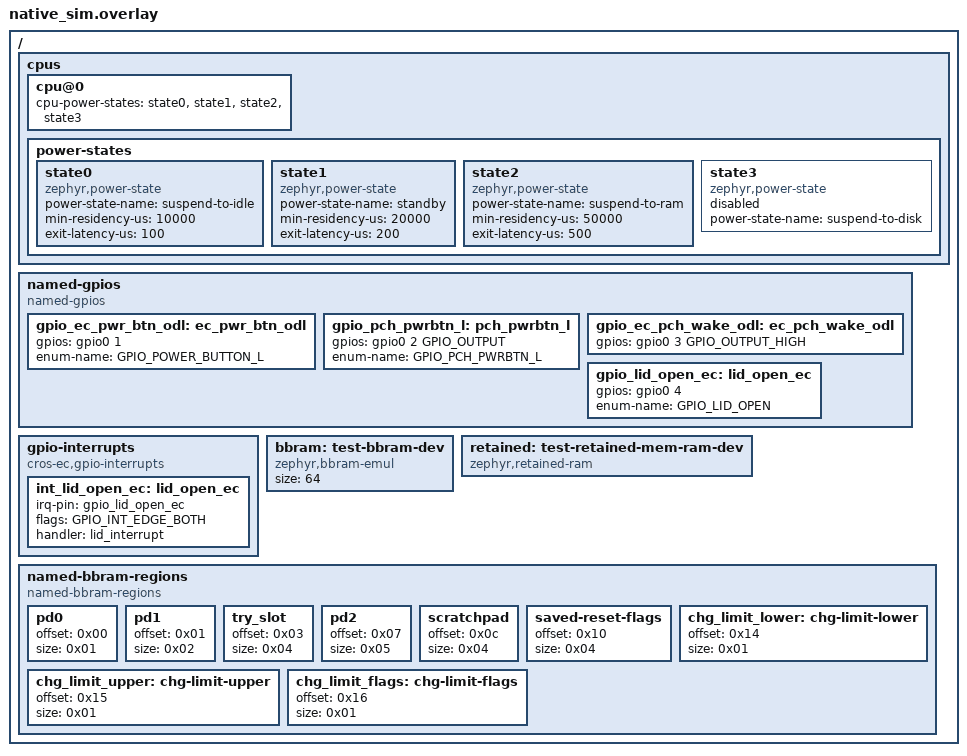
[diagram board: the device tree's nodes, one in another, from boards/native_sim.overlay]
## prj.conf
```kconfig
# Copyright 2021 The ChromiumOS Authors
# Use of this source code is governed by a BSD-style license that can be
# found in the LICENSE file.

CONFIG_ZTEST=y
CONFIG_PLATFORM_EC=y
CONFIG_CROS_EC=y
CONFIG_BBRAM=y

# Make console work
CONFIG_SERIAL=y
CONFIG_SHELL_BACKEND_DUMMY=y
CONFIG_SHELL_BACKEND_DUMMY_BUF_SIZE=1000
CONFIG_SHELL_BACKEND_SERIAL=n

# Make cros_system driver work
CONFIG_PM=y
CONFIG_CROS_SYSTEM_NATIVE_POSIX=y
```

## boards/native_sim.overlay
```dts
/* Copyright 2020 The ChromiumOS Authors
 * Use of this source code is governed by a BSD-style license that can be
 * found in the LICENSE file.
 */

#include <board-overlays/native_sim.dts>

/ {
	cpus {
		cpu@0 {
			cpu-power-states = <&state0 &state1 &state2 &state3>;
		};
		power-states {
			state0: state0 {
				compatible = "zephyr,power-state";
				power-state-name = "suspend-to-idle";
				min-residency-us = <10000>;
				exit-latency-us = <100>;
			};

			state1: state1 {
				compatible = "zephyr,power-state";
				power-state-name = "standby";
				min-residency-us = <20000>;
				exit-latency-us = <200>;
			};

			state2: state2 {
				compatible = "zephyr,power-state";
				power-state-name = "suspend-to-ram";
				min-residency-us = <50000>;
				exit-latency-us = <500>;
			};

			state3: state3 {
				compatible = "zephyr,power-state";
				power-state-name = "suspend-to-disk";
				status = "disabled";
			};
		};
	};
	named-gpios {
		compatible = "named-gpios";

		gpio_ec_pwr_btn_odl: ec_pwr_btn_odl {
			/* GPIO_PULL_UP will cause this start asserted,
			 * i.e. not pressed.
			 */
			gpios = <&gpio0 1 (GPIO_INPUT | GPIO_PULL_UP)>;
			enum-name = "GPIO_POWER_BUTTON_L";
		};
		gpio_pch_pwrbtn_l: pch_pwrbtn_l {
			gpios = <&gpio0 2 GPIO_OUTPUT>;
			enum-name = "GPIO_PCH_PWRBTN_L";
		};
		gpio_ec_pch_wake_odl: ec_pch_wake_odl {
			gpios = <&gpio0 3 GPIO_OUTPUT_HIGH>;
		};
		gpio_lid_open_ec: lid_open_ec {
			/* GPIO_PULL_UP will cause this start asserted. */
			gpios = <&gpio0 4 (GPIO_INPUT | GPIO_PULL_UP)>;
			enum-name = "GPIO_LID_OPEN";
		};
	};
	gpio-interrupts {
		compatible = "cros-ec,gpio-interrupts";

		int_lid_open_ec: lid_open_ec {
			irq-pin = <&gpio_lid_open_ec>;
			flags = <GPIO_INT_EDGE_BOTH>;
			handler = "lid_interrupt";
		};
	};
	bbram: test-bbram-dev {
		compatible = "zephyr,bbram-emul";
		size = <64>;
	};

	retained: test-retained-mem-ram-dev {
		compatible = "zephyr,retained-ram";
	};

	named-bbram-regions {
		compatible = "named-bbram-regions";
		pd0 {
			offset = <0x00>;
			size = <0x01>;
		};
		pd1 {
			offset = <0x01>;
			size = <0x02>;
		};
		try_slot {
			offset = <0x03>;
			size = <0x04>;
		};
		pd2 {
			offset = <0x07>;
			size = <0x05>;
		};
		scratchpad: scratchpad {
			offset = <0x0c>;
			size = <0x04>;
		};
		saved-reset-flags {
			offset = <0x10>;
			size = <0x04>;
		};
		chg_limit_lower: chg-limit-lower {
			offset = <0x14>;
			size = <0x01>;
		};
		chg_limit_upper: chg-limit-upper {
			offset = <0x15>;
			size = <0x01>;
		};
		chg_limit_flags: chg-limit-flags {
			offset = <0x16>;
			size = <0x01>;
		};
	};
};
```

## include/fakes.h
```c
/* Copyright 2022 The ChromiumOS Authors
 * Use of this source code is governed by a BSD-style license that can be
 * found in the LICENSE file.
 */

#ifndef PLATFORM_EC_ZEPHYR_TEST_SYSTEM_SHIM_INCLUDE_FAKES_H_
#define PLATFORM_EC_ZEPHYR_TEST_SYSTEM_SHIM_INCLUDE_FAKES_H_

#include "drivers/cros_system.h"

#include <stdint.h>

#include <zephyr/fff.h>

DECLARE_FAKE_VALUE_FUNC(int, cros_system_get_reset_cause);
DECLARE_FAKE_VALUE_FUNC(uint64_t, cros_system_deep_sleep_ticks);
DECLARE_FAKE_VALUE_FUNC(int, cros_system_hibernate, uint32_t, uint32_t);
DECLARE_FAKE_VALUE_FUNC(int, cros_system_get_hibernate_wake_source,
			enum hibernate_wake_source *);
DECLARE_FAKE_VALUE_FUNC(const char *, cros_system_chip_vendor);
DECLARE_FAKE_VALUE_FUNC(const char *, cros_system_chip_name);
DECLARE_FAKE_VALUE_FUNC(const char *, cros_system_chip_revision);
DECLARE_FAKE_VALUE_FUNC(int, cros_system_soc_reset);
DECLARE_FAKE_VOID_FUNC(watchdog_reload);
DECLARE_FAKE_VOID_FUNC(board_hibernate);

#endif /* PLATFORM_EC_ZEPHYR_TEST_SYSTEM_SHIM_INCLUDE_FAKES_H_ */
```

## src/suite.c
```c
/* Copyright 2022 The ChromiumOS Authors
 * Use of this source code is governed by a BSD-style license that can be
 * found in the LICENSE file.
 */

#include "fakes.h"

#include <zephyr/device.h>
#include <zephyr/drivers/bbram.h>
#include <zephyr/fff.h>
#include <zephyr/ztest.h>

DEFINE_FAKE_VALUE_FUNC(int, cros_system_get_reset_cause);
DEFINE_FAKE_VALUE_FUNC(uint64_t, cros_system_deep_sleep_ticks);
DEFINE_FAKE_VALUE_FUNC(int, cros_system_hibernate, uint32_t, uint32_t);
DEFINE_FAKE_VALUE_FUNC(int, cros_system_get_hibernate_wake_source,
		       enum hibernate_wake_source *);
DEFINE_FAKE_VALUE_FUNC(const char *, cros_system_chip_vendor);
DEFINE_FAKE_VALUE_FUNC(const char *, cros_system_chip_name);
DEFINE_FAKE_VALUE_FUNC(const char *, cros_system_chip_revision);
DEFINE_FAKE_VALUE_FUNC(int, cros_system_soc_reset);
DEFINE_FAKE_VOID_FUNC(watchdog_reload);
DEFINE_FAKE_VOID_FUNC(board_hibernate);

static void system_before_after(void *test_data)
{
#ifdef CONFIG_PLATFORM_EC_BBRAM_TYPE_BBRAM
	const struct device *bbram_dev =
		DEVICE_DT_GET_OR_NULL(DT_CHOSEN(cros_ec_bbram));

	if (bbram_dev != NULL) {
		bbram_emul_set_invalid(bbram_dev, false);
	}
#endif

	RESET_FAKE(cros_system_get_reset_cause);
	RESET_FAKE(cros_system_deep_sleep_ticks);
	RESET_FAKE(cros_system_hibernate);
	RESET_FAKE(cros_system_get_hibernate_wake_source);
	RESET_FAKE(cros_system_chip_vendor);
	RESET_FAKE(cros_system_chip_name);
	RESET_FAKE(cros_system_chip_revision);
	RESET_FAKE(cros_system_soc_reset);
	RESET_FAKE(watchdog_reload);
	RESET_FAKE(board_hibernate);
}

ZTEST_SUITE(system, NULL, NULL, system_before_after, system_before_after, NULL);
```

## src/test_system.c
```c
/* Copyright 2020 The ChromiumOS Authors
 * Use of this source code is governed by a BSD-style license that can be
 * found in the LICENSE file.
 */

#include "bbram.h"
#include "drivers/cros_system.h"
#include "fakes.h"
#include "system.h"

#include <setjmp.h>

#include <zephyr/device.h>
#include <zephyr/drivers/bbram.h>
#include <zephyr/drivers/retained_mem.h>
#include <zephyr/fff.h>
#include <zephyr/logging/log.h>
#include <zephyr/pm/policy.h>
#include <zephyr/pm/state.h>
#include <zephyr/shell/shell_dummy.h>
#include <zephyr/ztest_assert.h>
#include <zephyr/ztest_test.h>

LOG_MODULE_REGISTER(test);

static char mock_data[64] =
	"abcdefghijklmnopqrstuvwxyzABCDEFGHIJKLMNOPQRSTUVWXYZ0123456789!@";

BUILD_ASSERT(sizeof(mock_data) >= BBRAM_REGION_OFFSET(chg_limit_flags) +
					  BBRAM_REGION_SIZE(chg_limit_flags));

int system_preinitialize(const struct device *unused);
int system_bbram_write(const struct device *dev, size_t offset, size_t size,
		       const uint8_t *data);

ZTEST(system, test_invalid_bbram_index)
{
	zassert_equal(EC_ERROR_INVAL,
		      system_get_bbram(SYSTEM_BBRAM_IDX_MAX, NULL));
	zassert_equal(EC_ERROR_INVAL,
		      system_set_bbram(SYSTEM_BBRAM_IDX_MAX, 0));
}

ZTEST(system, test_bbram_get)
{
	const struct device *const bbram_dev =
		DEVICE_DT_GET(DT_CHOSEN(cros_ec_bbram));
	uint8_t output[10];
	int rc;

	/* Write expected data to read back */
	rc = system_bbram_write(bbram_dev, 0, ARRAY_SIZE(mock_data), mock_data);
	zassert_ok(rc);

	rc = system_get_bbram(SYSTEM_BBRAM_IDX_PD0, output);
	zassert_ok(rc);
	zassert_mem_equal(output, mock_data + BBRAM_REGION_OFFSET(pd0),
			  BBRAM_REGION_SIZE(pd0), NULL);

	rc = system_get_bbram(SYSTEM_BBRAM_IDX_PD1, output);
	zassert_ok(rc);
	zassert_mem_equal(output, mock_data + BBRAM_REGION_OFFSET(pd1),
			  BBRAM_REGION_SIZE(pd1), NULL);

	rc = system_get_bbram(SYSTEM_BBRAM_IDX_PD2, output);
	zassert_ok(rc);
	zassert_mem_equal(output, mock_data + BBRAM_REGION_OFFSET(pd2),
			  BBRAM_REGION_SIZE(pd2), NULL);

	rc = system_get_bbram(SYSTEM_BBRAM_IDX_TRY_SLOT, output);
	zassert_ok(rc);
	zassert_mem_equal(output, mock_data + BBRAM_REGION_OFFSET(try_slot),
			  BBRAM_REGION_SIZE(try_slot), NULL);

	rc = system_get_bbram(SYSTEM_BBRAM_IDX_CHG_LIMIT_LOWER, output);
	zassert_ok(rc);
	zassert_mem_equal(output,
			  mock_data + BBRAM_REGION_OFFSET(chg_limit_lower),
			  BBRAM_REGION_SIZE(chg_limit_lower), NULL);

	rc = system_get_bbram(SYSTEM_BBRAM_IDX_CHG_LIMIT_UPPER, output);
	zassert_ok(rc);
	zassert_mem_equal(output,
			  mock_data + BBRAM_REGION_OFFSET(chg_limit_upper),
			  BBRAM_REGION_SIZE(chg_limit_upper), NULL);

	rc = system_get_bbram(SYSTEM_BBRAM_IDX_CHG_LIMIT_FLAGS, output);
	zassert_ok(rc);
	zassert_mem_equal(output,
			  mock_data + BBRAM_REGION_OFFSET(chg_limit_flags),
			  BBRAM_REGION_SIZE(chg_limit_flags), NULL);
}

ZTEST(system, test_bbram_set_get)
{
	uint8_t val;

	zassert_ok(system_set_bbram(SYSTEM_BBRAM_IDX_CHG_LIMIT_LOWER, 80));
	zassert_ok(system_get_bbram(SYSTEM_BBRAM_IDX_CHG_LIMIT_LOWER, &val));
	zassert_equal(val, 80);

	zassert_ok(system_set_bbram(SYSTEM_BBRAM_IDX_CHG_LIMIT_UPPER, 85));
	zassert_ok(system_get_bbram(SYSTEM_BBRAM_IDX_CHG_LIMIT_UPPER, &val));
	zassert_equal(val, 85);

	zassert_ok(system_set_bbram(SYSTEM_BBRAM_IDX_CHG_LIMIT_FLAGS, 1));
	zassert_ok(system_get_bbram(SYSTEM_BBRAM_IDX_CHG_LIMIT_FLAGS, &val));
	zassert_equal(val, 1);
}

ZTEST(system, test_save_read_chip_reset_flags)
{
	uint32_t arbitrary_flags = 0x1234;

	chip_save_reset_flags(0);
	chip_save_reset_flags(arbitrary_flags);
	zassert_equal(chip_read_reset_flags(), arbitrary_flags);
}

static int
custom_cros_system_get_hibernate_wake_source(enum hibernate_wake_source *source)
{
	*source = WAKE_SOURCE_PWR_BTN;
	return 0;
}

/* Test system_get_hibernate_wake_source delegates to cros_system driver */
ZTEST(system, test_system_get_hibernate_wake_source)
{
	enum hibernate_wake_source source = WAKE_SOURCE_UNKNOWN;

	/* Test successful query with custom fake setting the out parameter */
	cros_system_get_hibernate_wake_source_fake.custom_fake =
		custom_cros_system_get_hibernate_wake_source;

	zassert_ok(system_get_hibernate_wake_source(&source));
	zassert_equal(cros_system_get_hibernate_wake_source_fake.call_count, 1);
	zassert_equal(cros_system_get_hibernate_wake_source_fake.arg0_val,
		      &source);
	zassert_equal(source, WAKE_SOURCE_PWR_BTN);

	/* Test error return value is properly forwarded */
	cros_system_get_hibernate_wake_source_fake.custom_fake = NULL;
	cros_system_get_hibernate_wake_source_fake.return_val = -ENOSYS;

	zassert_equal(-ENOSYS, system_get_hibernate_wake_source(&source));
	zassert_equal(cros_system_get_hibernate_wake_source_fake.call_count, 2);
}

ZTEST(system, test_system_set_get_scratchpad)
{
	/* Arbitrary values */
	uint32_t scratch_set = 0x1234;
	uint32_t scratch_read;

	system_set_scratchpad(scratch_set);
	system_get_scratchpad(&scratch_read);
	zassert_equal(scratch_read, scratch_set);
}

#ifdef CONFIG_PLATFORM_EC_BBRAM_TYPE_BBRAM
ZTEST(system, test_system_get_scratchpad_fail)
{
	const struct device *bbram_dev =
		DEVICE_DT_GET(DT_CHOSEN(cros_ec_bbram));

	zassert_ok(bbram_emul_set_invalid(bbram_dev, true));
	zassert_equal(-EC_ERROR_INVAL, system_get_scratchpad(NULL));
}
#endif /* CONFIG_PLATFORM_EC_BBRAM_TYPE_BBRAM */

static jmp_buf jmp_hibernate;

static int _test_cros_system_hibernate(uint32_t seconds, uint32_t microseconds)
{
	longjmp(jmp_hibernate, 1);

	return 0;
}

ZTEST(system, test_system_hibernate)
{
	/*
	 * Due to setjmp usage, this test provides no coverage, but does
	 * actually cover the code. This is due to a bug in LCOV.
	 */
	int ret = setjmp(jmp_hibernate);
	/* Validate 0th and last bit preserved*/
	uint32_t secs = BIT(31) + 1;
	uint32_t msecs = BIT(31) + 3;

	cros_system_hibernate_fake.custom_fake = _test_cros_system_hibernate;

	if (ret == 0) {
		system_hibernate(secs, msecs);
	}

	zassert_not_equal(ret, 0);

	zassert_equal(cros_system_hibernate_fake.call_count, 1);
	zassert_equal(cros_system_hibernate_fake.arg0_val, secs);
	zassert_equal(cros_system_hibernate_fake.arg1_val, msecs);
	zassert_equal(board_hibernate_fake.call_count, 1);
}

ZTEST(system, test_system_hibernate__failure)
{
	/* Validate 0th and last bit preserved*/
	uint32_t secs = BIT(31) + 1;
	uint32_t msecs = BIT(31) + 3;

	cros_system_hibernate_fake.return_val = -1;

	system_hibernate(secs, msecs);

	zassert_equal(cros_system_hibernate_fake.call_count, 1);
	zassert_equal(cros_system_hibernate_fake.arg0_val, secs);
	zassert_equal(cros_system_hibernate_fake.arg1_val, msecs);
}

ZTEST(system, test_system_get_chip_values)
{
	/* Vendor */
	cros_system_chip_vendor_fake.return_val = "a";
	zassert_mem_equal(system_get_chip_vendor(), "a", sizeof("a"));
	zassert_equal(cros_system_chip_vendor_fake.call_count, 1);

	/* Name */
	cros_system_chip_name_fake.return_val = "b";
	zassert_mem_equal(system_get_chip_name(), "b", sizeof("b"));
	zassert_equal(cros_system_chip_name_fake.call_count, 1);

	/* Revision */
	cros_system_chip_revision_fake.return_val = "c";
	zassert_mem_equal(system_get_chip_revision(), "c", sizeof("c"));
	zassert_equal(cros_system_chip_revision_fake.call_count, 1);
}

static int _test_cros_system_soc_reset(void)
{
	printf("called from soc reset");
	longjmp(jmp_hibernate, 1);

	return 0;
}

ZTEST(system, test_system_reset)
{
	/*
	 * Despite using setjmp this test consistently covers the code under
	 * test. Context: https://github.com/llvm/llvm-project/issues/50119
	 */
	int ret = setjmp(jmp_hibernate);
	uint32_t arbitrary_flags_w_reset_wait_ext = 0x1234 |
						    SYSTEM_RESET_WAIT_EXT;
	uint32_t encoded_arbitrary_flags_w_reset_wait_ext;

	system_encode_save_flags(arbitrary_flags_w_reset_wait_ext,
				 &encoded_arbitrary_flags_w_reset_wait_ext);

	cros_system_soc_reset_fake.custom_fake = _test_cros_system_soc_reset;

	if (ret == 0) {
		system_reset(arbitrary_flags_w_reset_wait_ext);
	}

	zassert_equal(chip_read_reset_flags(),
		      encoded_arbitrary_flags_w_reset_wait_ext);

	zassert_equal(watchdog_reload_fake.call_count, 1000);
	zassert_equal(cros_system_soc_reset_fake.call_count, 1);
}

ZTEST_USER(system, test_system_console_cmd__idlestats)
{
	const struct shell *shell_zephyr = get_ec_shell();
	const char *outbuffer;
	size_t buffer_size;

	shell_backend_dummy_clear_output(shell_zephyr);

	k_sleep(K_SECONDS(1));
	zassert_ok(shell_execute_cmd(shell_zephyr, "idlestats"), NULL);

	/* Weakly verify contents */
	outbuffer = shell_backend_dummy_get_output(shell_zephyr, &buffer_size);
	zassert_not_equal(buffer_size, 0);
	zassert_not_null(strstr(outbuffer, "Time spent in deep-sleep:"));
	zassert_not_null(strstr(outbuffer, "Total time on:"));

	zassert_equal(cros_system_deep_sleep_ticks_fake.call_count, 1);
}

ZTEST(system, test_init_invalid_reset_cause)
{
	cros_system_get_reset_cause_fake.return_val = -1;
	zassert_equal(-1, system_preinitialize(NULL));
}

ZTEST(system, test_init_cause_vcc1_rst_pin)
{
	cros_system_get_reset_cause_fake.return_val = VCC1_RST_PIN;
	chip_save_reset_flags(0);
	system_clear_reset_flags(0xffffffff);

	zassert_ok(system_preinitialize(NULL));
	zassert_equal(EC_RESET_FLAG_RESET_PIN, system_get_reset_flags());
}

ZTEST(system, test_init_cause_debug_rst)
{
	cros_system_get_reset_cause_fake.return_val = DEBUG_RST;
	chip_save_reset_flags(0);
	system_clear_reset_flags(0xffffffff);

	zassert_ok(system_preinitialize(NULL));
	zassert_equal(EC_RESET_FLAG_SOFT, system_get_reset_flags());
}

ZTEST(system, test_init_cause_watchdog_rst)
{
	cros_system_get_reset_cause_fake.return_val = WATCHDOG_RST;
	chip_save_reset_flags(0);
	system_clear_reset_flags(0xffffffff);

	zassert_ok(system_preinitialize(NULL));
	zassert_equal(EC_RESET_FLAG_WATCHDOG, system_get_reset_flags());
}

ZTEST(system, test_lock_all_power_states)
{
	const struct pm_state_info *cpu_states;
	uint8_t num_cpu_states = pm_state_cpu_get_all(0U, &cpu_states);

	pm_policy_state_lock_get_all();

	for (uint8_t i = 0; i < num_cpu_states; ++i) {
		zassert_false(
			pm_policy_state_is_available(cpu_states[i].state,
						     cpu_states[i].substate_id),
			"Expected CPU state %d to be unavailable (%d::%d)", i,
			cpu_states[i].state, cpu_states[i].substate_id);
	}

	pm_policy_state_lock_put_all();

	for (uint8_t i = 0; i < num_cpu_states; ++i) {
		zassert_true(
			pm_policy_state_is_available(cpu_states[i].state,
						     cpu_states[i].substate_id),
			"Expected CPU state %d to be ailable (%d::%d)", i,
			cpu_states[i].state, cpu_states[i].substate_id);
	}
}

#ifdef CONFIG_PLATFORM_EC_BBRAM_TYPE_RETAINED_MEM
/* 64 bytes + 2 bytes for CRC. */
#define BBRAM_SIZE (64 + 2)
static uint8_t bbram_buf[BBRAM_SIZE];

static ssize_t retained_mem_ram_sim_size(const struct device *dev)
{
	return BBRAM_SIZE;
}

static int retained_mem_ram_sim_read(const struct device *dev, off_t offset,
				     uint8_t *buffer, size_t size)
{
	memcpy(buffer, (bbram_buf + offset), size);
	return 0;
}

static int retained_mem_ram_sim_write(const struct device *dev, off_t offset,
				      const uint8_t *buffer, size_t size)
{
	memcpy((bbram_buf + offset), buffer, size);
	return 0;
}

static int retained_mem_ram_sim_clear(const struct device *dev)
{
	memset(bbram_buf, 0, BBRAM_SIZE);
	return 0;
}

static DEVICE_API(retained_mem, retained_mem_ram_sim_api) = {
	.size = retained_mem_ram_sim_size,
	.read = retained_mem_ram_sim_read,
	.write = retained_mem_ram_sim_write,
	.clear = retained_mem_ram_sim_clear,
};
DEVICE_DT_DEFINE(DT_CHOSEN(cros_ec_bbram), NULL, NULL, NULL, NULL, PRE_KERNEL_1,
		 10, &retained_mem_ram_sim_api)
#endif /* CONFIG_PLATFORM_EC_BBRAM_TYPE_RETAINED_MEM */
```
